# SKEAZN642 register map
File version: 1.6
SKEAZN642 Freescale Microcontroller
Registers are 8-bit, read-write, reset 0x0 unless marked. A register's access mark holds for its fields unless they carry their own. Offsets are from the block's base; lines under a group give offsets from that group; [hi:lo] are bit positions; {n}, {i} and the like mark numbered series; 'fields as' and 'values as' point back to an identical list; <NAME> marks a mode.

## Memory map
0x00000400 FTMRH_FlashConfig size 0x10 — Flash configuration field
0x40020000 FTMRH size 0xD — Flash Memory
0x40031000 IRQ size 0x1 — Interrupt
0x40032000 CRC size 0xC — Cyclic Redundancy Check
0x40037000 PIT size 0x120 — Periodic Interrupt Timer
0x40038000 FTM0 size 0x1C — FlexTimer Module
0x40039000 FTM1 size 0x1C — FlexTimer Module
0x4003A000 FTM2 size 0x9C — FlexTimer Module
0x4003B000 ADC size 0x1C — Analog-to-digital converter
0x4003D000 RTC size 0xC — Real-time counter
0x40048000 SIM size 0x1C — System Integration Module
0x40049000 PORT size 0x10 — Port control and interrupts
0x40052000 WDOG size 0x8 — Watchdog timer
0x40064000 ICS size 0x5 — Clock management
0x40065000 OSC size 0x1 — Oscillator
0x40066000 I2C0 size 0xC — Inter-Integrated Circuit
0x4006A000 UART0 size 0x8 — Universal Asynchronous Receiver/Transmitter (UART)
0x4006B000 UART1 size 0x8 — Universal Asynchronous Receiver/Transmitter (UART)
0x4006C000 UART2 size 0x8 — Universal Asynchronous Receiver/Transmitter (UART)
0x40073000 ACMP0 size 0x4 — Analog comparator
0x40074000 ACMP1 size 0x4 — Analog comparator
0x40076000 SPI0 size 0x8 — Serial Peripheral Interface
0x40077000 SPI1 size 0x8 — Serial Peripheral Interface
0x40079000 KBI0 size 0x3 — Keyboard interrupts
0x4007A000 KBI1 size 0x3 — Keyboard interrupts
0x4007D000 PMC size 0x2 — Power management
0x400FF000 GPIOA size 0x1C — General Purpose Input/Output
0x400FF040 GPIOB size 0x1C — General Purpose Input/Output
0xF0002000 ROM size 0x1000 — System ROM
0xF0003000 MCM blocks up to offset 0x10 — Core Platform Miscellaneous Control Module
0xF8000000 FGPIOA size 0x1C — General Purpose Input/Output
0xF8000040 FGPIOB size 0x1C — General Purpose Input/Output

## Interrupts
5 INT_FTMRH (FTMRH)
6 INT_LVD_LVW (PMC)
7 INT_IRQ (IRQ)
8 INT_I2C0 (I2C0)
10 INT_SPI0 (SPI0)
11 INT_SPI1 (SPI1)
12 INT_UART0 (UART0)
13 INT_UART1 (UART1)
14 INT_UART2 (UART2)
15 INT_ADC0 (ADC)
16 INT_ACMP0 (ACMP0)
17 INT_FTM0 (FTM0)
18 INT_FTM1 (FTM1)
19 INT_FTM2 (FTM2)
20 INT_RTC (RTC)
21 INT_ACMP1 (ACMP1)
22 INT_PIT_CH0 (PIT)
23 INT_PIT_CH1 (PIT)
24 INT_KBI0 (KBI0)
25 INT_KBI1 (KBI1)
27 INT_ICS (ICS)
28 INT_Watchdog (WDOG)

## FTMRH_FlashConfig — Flash configuration field
Base 0x00000400; register names take the prefix NV_
{0x0+i} BACKKEY{i} ro reset 0xFF (i=0..7) — Backdoor Comparison Key {i}
  [7:0] KEY — Backdoor Comparison Key.
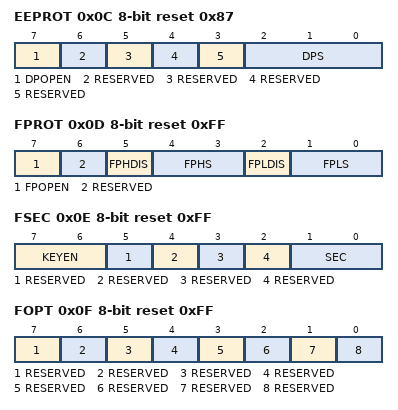
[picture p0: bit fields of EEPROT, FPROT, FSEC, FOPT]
0x0C EEPROT ro reset 0x87 — Non-volatile E-Flash Protection Register
  [7] DPOPEN, [6] RESERVED, [5] RESERVED, [4] RESERVED, [3] RESERVED, [2:0] DPS
0x0D FPROT ro reset 0xFF — Non-volatile P-Flash Protection Register
  [7] FPOPEN, [6] RESERVED, [5] FPHDIS, [4:3] FPHS, [2] FPLDIS, [1:0] FPLS
0x0E FSEC ro reset 0xFF — Non-volatile Flash Security Register
  [7:6] KEYEN — Backdoor Key Security Enable
  [5] RESERVED
  [4] RESERVED
  [3] RESERVED
  [2] RESERVED
  [1:0] SEC — Flash Security
0x0F FOPT ro reset 0xFF — Non-volatile Flash Option Register
  [7] RESERVED, [6] RESERVED, [5] RESERVED, [4] RESERVED, [3] RESERVED, [2] RESERVED, [1] RESERVED, [0] RESERVED

## IRQ — Interrupt
Base 0x40031000; register names take the prefix IRQ_
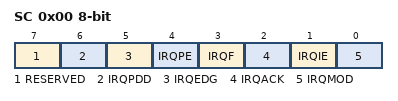
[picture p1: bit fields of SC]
0x00 SC — Interrupt Pin Request Status and Control Register
  [7] RESERVED ro
  [6] IRQPDD — Interrupt Request (IRQ) Pull Device Disable
    0=IRQ pull device enabled if IRQPE = 1; 1=IRQ pull device disabled if IRQPE = 1
  [5] IRQEDG — Interrupt Request (IRQ) Edge Select
    0=IRQ is falling-edge or falling-edge/low-level sensitive; 1=IRQ is rising-edge or rising-edge/high-level sensitive
  [4] IRQPE — IRQ Pin Enable
    0=IRQ pin function is disabled; 1=IRQ pin function is enabled
  [3] IRQF ro — IRQ Flag
    0=No IRQ request; 1=IRQ event is detected
  [2] IRQACK wo — IRQ Acknowledge
  [1] IRQIE — IRQ Interrupt Enable
    0=Interrupt request when IRQF set is disabled (use polling); 1=Interrupt requested whenever IRQF = 1
  [0] IRQMOD — IRQ Detection Mode
    0=IRQ event is detected only on falling/rising edges; 1=IRQ event is detected on falling/rising edges and low/high levels
